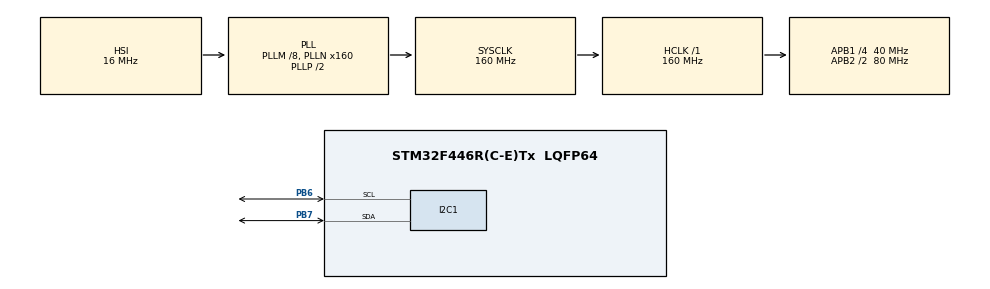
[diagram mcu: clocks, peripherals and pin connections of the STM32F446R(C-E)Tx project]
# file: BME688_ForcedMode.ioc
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Mcu.Family=STM32F4
Mcu.Name=STM32F446R(C-E)Tx
Mcu.Package=LQFP64
NVIC.PriorityGroup=NVIC_PRIORITYGROUP_0
PB6.Mode=I2C
PB6.Signal=I2C1_SCL
PB7.Mode=I2C
PB7.Signal=I2C1_SDA
PH0-OSC_IN.Mode=HSE-External-Clock-Source
PH0-OSC_IN.Signal=RCC_OSC_IN
PH1-OSC_OUT.Mode=HSE-External-Clock-Source
PH1-OSC_OUT.Signal=RCC_OSC_OUT
ProjectManager.HeapSize=0x200
ProjectManager.StackSize=0x400
ProjectManager.TargetToolchain=STM32CubeIDE
RCC.AHBFreq_Value=160000000
RCC.APB1CLKDivider=RCC_HCLK_DIV4
RCC.APB1Freq_Value=40000000
RCC.APB1TimFreq_Value=80000000
RCC.APB2CLKDivider=RCC_HCLK_DIV2
RCC.APB2Freq_Value=80000000
RCC.APB2TimFreq_Value=160000000
RCC.CortexFreq_Value=160000000
RCC.FLatency-AdvancedSettings=FLASH_LATENCY_5
RCC.HCLKFreq_Value=160000000
RCC.HSE_VALUE=8000000
RCC.HSI_VALUE=16000000
RCC.PLLM=8
RCC.PLLN=160
RCC.SYSCLKFreq_VALUE=160000000
RCC.SYSCLKSource=RCC_SYSCLKSOURCE_PLLCLK
RCC.USBFreq_Value=160000000
RCC.VCOOutputFreq_Value=320000000
board=NUCLEO-F446RE

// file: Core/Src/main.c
/* USER CODE BEGIN Header */
/* <hazinvogue> */
/**
  ******************************************************************************
  * @file           : main.c
  * @brief          : Main program body
  ******************************************************************************
  * @attention
  *
  * Copyright (c) 2023 STMicroelectronics.
  * All rights reserved.
  *
  * This software is licensed under terms that can be found in the LICENSE file
  * in the root directory of this software component.
  * If no LICENSE file comes with this software, it is provided AS-IS.
  *
  ******************************************************************************
  */
/* USER CODE END Header */
#include "main.h"

/* USER CODE BEGIN Includes */

#include<stdio.h>
#include <string.h>
#include <stdlib.h>
#include <math.h>
#include "bme68x.h"
#include "stm32f4xx.h"
#include "bme68x_defs.h"
#include "portbme.h"

/* USER CODE END Includes */

/* USER CODE BEGIN PTD */

#define SAMPLE_COUNT  UINT16_C(300)

/* USER CODE END PTD */

I2C_HandleTypeDef hi2c1;

/* USER CODE BEGIN PV */

struct bme68x_dev bme;
int8_t rslt;
struct bme68x_conf conf;
struct bme68x_heatr_conf heatr_conf;
struct bme68x_data data;
uint32_t del_period;
uint32_t time_ms = 0;
uint8_t n_fields;
uint16_t sample_count = 1;

/* USER CODE END PV */

void SystemClock_Config(void);
static void MX_GPIO_Init(void);
static void MX_I2C1_Init(void);

int main(void)
{

  /* MCU Configuration--------------------------------------------------------*/

  /* Reset of all peripherals, Initializes the Flash interface and the Systick. */
  HAL_Init();

  /* Configure the system clock */
  SystemClock_Config();

  /* Initialize all configured peripherals */
  MX_GPIO_Init();
  MX_I2C1_Init();
  /* USER CODE BEGIN 2 */

	bme68x_soft_reset(&bme);

	rslt = bme68x_interface_init(&bme, BME68X_I2C_INTF);
	bme68x_check_rslt("bme68x_interface_init", rslt);

	rslt = bme68x_init(&bme);
	bme68x_check_rslt("bme68x_init", rslt);

	conf.filter = BME68X_FILTER_OFF;
	conf.odr = BME68X_ODR_NONE;
	conf.os_hum = BME68X_OS_16X;
	conf.os_pres = BME68X_OS_1X;
	conf.os_temp = BME68X_OS_2X;
	rslt = bme68x_set_conf(&conf, &bme);
	bme68x_check_rslt("bme68x_set_conf", rslt);

	heatr_conf.enable = BME68X_ENABLE;
	heatr_conf.heatr_temp = 300;
	heatr_conf.heatr_dur = 100;
	rslt = bme68x_set_heatr_conf(BME68X_FORCED_MODE, &heatr_conf, &bme);
	bme68x_check_rslt("bme68x_set_heatr_conf", rslt);

	printf("Sample, TimeStamp(ms), Temperature(deg C), Pressure(Pa), Humidity(%%), Gas resistance(ohm), Status\n");

  /* USER CODE END 2 */

  /* Infinite loop */
  /* USER CODE BEGIN WHILE */
  while (1)
  {

      	  while (sample_count <= SAMPLE_COUNT)
      	  {
          rslt = bme68x_set_op_mode(BME68X_FORCED_MODE, &bme);
          bme68x_check_rslt("bme68x_set_op_mode", rslt);

          del_period = bme68x_get_meas_dur(BME68X_FORCED_MODE, &conf, &bme) + (heatr_conf.heatr_dur * 1000);
          bme.delay_us(0, bme.intf_ptr);

          rslt = bme68x_get_data(BME68X_FORCED_MODE, &data, &n_fields, &bme);
          bme68x_check_rslt("bme68x_get_data", rslt);

          if (n_fields)
          {
  #ifdef BME68X_USE_FPU
			printf("%u, %lu, %.2f, %.2f, %.2f, %.2f, 0x%x\n",
			sample_count,
			(long unsigned int)time_ms,
			data.temperature,
			data.pressure,
			data.humidity,
			data.gas_resistance,
			data.status);
  #else
			printf("%u, %lu, %d, %lu, %lu, %lu, 0x%x\n",
			sample_count,
			(long unsigned int)time_ms,
			(data.temperature / 100),
			(long unsigned int)data.pressure,
			(long unsigned int)(data.humidity / 1000),
			(long unsigned int)data.gas_resistance,
			data.status);
  #endif

  sample_count++;

          }
  }
  return rslt;

    /* USER CODE END WHILE */

  }
}

void SystemClock_Config(void)
{
  RCC_OscInitTypeDef RCC_OscInitStruct = {0};
  RCC_ClkInitTypeDef RCC_ClkInitStruct = {0};

  /** Configure the main internal regulator output voltage
  */
  __HAL_RCC_PWR_CLK_ENABLE();
  __HAL_PWR_VOLTAGESCALING_CONFIG(PWR_REGULATOR_VOLTAGE_SCALE1);

  /** Initializes the RCC Oscillators according to the specified parameters
  * in the RCC_OscInitTypeDef structure.
  */
  RCC_OscInitStruct.OscillatorType = RCC_OSCILLATORTYPE_HSI;
  RCC_OscInitStruct.HSIState = RCC_HSI_ON;
  RCC_OscInitStruct.HSICalibrationValue = RCC_HSICALIBRATION_DEFAULT;
  RCC_OscInitStruct.PLL.PLLState = RCC_PLL_ON;
  RCC_OscInitStruct.PLL.PLLSource = RCC_PLLSOURCE_HSI;
  RCC_OscInitStruct.PLL.PLLM = 8;
  RCC_OscInitStruct.PLL.PLLN = 160;
  RCC_OscInitStruct.PLL.PLLP = RCC_PLLP_DIV2;
  RCC_OscInitStruct.PLL.PLLQ = 2;
  RCC_OscInitStruct.PLL.PLLR = 2;
  if (HAL_RCC_OscConfig(&RCC_OscInitStruct) != HAL_OK)
  {
    Error_Handler();
  }

  /** Initializes the CPU, AHB and APB buses clocks
  */
  RCC_ClkInitStruct.ClockType = RCC_CLOCKTYPE_HCLK|RCC_CLOCKTYPE_SYSCLK
                              |RCC_CLOCKTYPE_PCLK1|RCC_CLOCKTYPE_PCLK2;
  RCC_ClkInitStruct.SYSCLKSource = RCC_SYSCLKSOURCE_PLLCLK;
  RCC_ClkInitStruct.AHBCLKDivider = RCC_SYSCLK_DIV1;
  RCC_ClkInitStruct.APB1CLKDivider = RCC_HCLK_DIV4;
  RCC_ClkInitStruct.APB2CLKDivider = RCC_HCLK_DIV2;

  if (HAL_RCC_ClockConfig(&RCC_ClkInitStruct, FLASH_LATENCY_5) != HAL_OK)
  {
    Error_Handler();
  }
}

static void MX_I2C1_Init(void)
{

  hi2c1.Instance = I2C1;
  hi2c1.Init.ClockSpeed = 100000;
  hi2c1.Init.DutyCycle = I2C_DUTYCYCLE_2;
  hi2c1.Init.OwnAddress1 = 0;
  hi2c1.Init.AddressingMode = I2C_ADDRESSINGMODE_7BIT;
  hi2c1.Init.DualAddressMode = I2C_DUALADDRESS_DISABLE;
  hi2c1.Init.OwnAddress2 = 0;
  hi2c1.Init.GeneralCallMode = I2C_GENERALCALL_DISABLE;
  hi2c1.Init.NoStretchMode = I2C_NOSTRETCH_DISABLE;
  if (HAL_I2C_Init(&hi2c1) != HAL_OK)
  {
    Error_Handler();
  }

}

static void MX_GPIO_Init(void)
{

  /* GPIO Ports Clock Enable */
  __HAL_RCC_GPIOH_CLK_ENABLE();
  __HAL_RCC_GPIOB_CLK_ENABLE();

}

void Error_Handler(void)
{
  __disable_irq();
  while (1)
  {
  }
}
